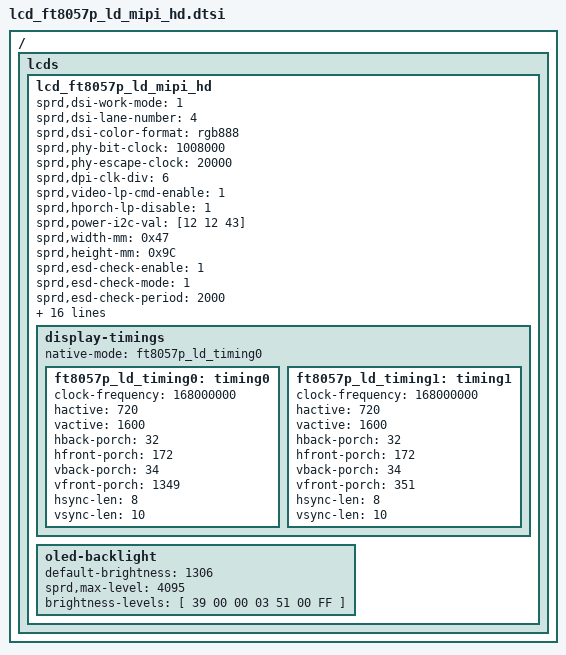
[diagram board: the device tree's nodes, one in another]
/*
 * R61350 Truly LCD config dtsi file for spreadtrum
 *
 * Copyright (C) 2018, Spreadtrum Communications Inc.
 *
 * SPDX-License-Identifier: (GPL-2.0+ OR MIT)
 */

/ {
	fragment {
		target-path = "/";
		__overlay__ {
			lcds {
				lcd_ft8057p_ld_mipi_hd: lcd_ft8057p_ld_mipi_hd {

					sprd,dsi-work-mode = <1>; /* video burst mode*/
					sprd,dsi-lane-number = <4>;
					sprd,dsi-color-format = "rgb888";

					sprd,phy-bit-clock = <1008000>;	/* kbps */
					sprd,phy-escape-clock = <20000>;/* kHz */
					/*add for mipi-6-way frequency mode */
					sprd,dpi-clk-div = <6>;
					sprd,video-lp-cmd-enable = <1>;
					sprd,hporch-lp-disable = <1>;

                                       sprd,power-i2c-val = [12 12 43];

					sprd,width-mm = <0x47>;
					sprd,height-mm = <0x9C>;
					sprd,esd-check-enable = <1>;
					sprd,esd-check-mode = <1>;
					sprd,esd-check-period = <2000>;
					/* sprd,esd-check-register = <0x0A>; */
					/* sprd,esd-check-value = <0x9C>; */

                                       sprd,ft8057-sequence = <1>;
					sprd,reset-on-sequence = <1 5>, <0 5>, <1 30>;
					sprd,reset-off-sequence = <1 5>;
					sprd,use-high-bit-mode = <1>;
					//sprd,use-dcs-write;
					/*
					 * Use 4 bits number for descripting video lp mode, and it can be combined used.
					 * BIT(0): allow vactive enter lp;
					 * BIT(1): allow vfp enter lp;
					 * BIT(2): allow vbp enter lp;
					 * BIT(3): allow vsa enter lp;
					 * For example:
					 * If we need vfp & vbp enter lp, we can calculate this value as a result of BIT(1) | BIT(2)
					 * And we get the result of 3 and set this value to lcd dt property sprd,video-lp-en-mode.
					 * If we need all stage can enter lp, we can calculate this value as a result of BIT(0) | BIT(1) | BIT(2) | BIT(3).
					 * And we get the result of 15 and set this value to lcd dt property sprd,video-lp-en-mode.
					 */
					sprd,video-lp-en-mode = <2>;
					sprd,initial-command = [
					29 00 00 02 00 00
					29 00 00 04 FF 80 57 01
					29 00 00 02 00 80
					29 00 00 03 FF 80 57
					29 00 00 02 00 00
					29 00 00 05 2A 00 00 02 CF
					29 00 00 02 00 00
					29 00 00 05 2B 00 00 06 3F
					29 00 00 02 00 A3
					29 00 00 05 B3 06 40 00 18
					29 00 00 02 00 93
					29 00 00 02 C5 57
					29 00 00 02 00 97
					29 00 00 02 C5 57
					29 00 00 02 00 9A
					29 00 00 02 C5 CB
					29 00 00 02 00 9C
					29 00 00 02 C5 CB
					29 00 00 02 00 B6
					29 00 00 03 C5 43 43
					29 00 00 02 00 B8
					29 00 00 03 C5 41 41
					29 00 00 02 00 00
					29 00 00 03 D8 33 33
					29 00 00 02 00 82
					29 00 00 02 C5 55
					29 00 00 02 00 83
					29 00 00 02 C5 07
					29 00 00 02 00 96
					29 00 00 02 F5 19
					29 00 00 02 00 86
					29 00 00 02 F5 19
					29 00 00 02 00 94
					29 00 00 02 C5 15
					29 00 00 02 00 9B
					29 00 00 02 C5 51
					29 00 00 02 00 A3
					29 00 00 02 A5 04
					29 00 00 02 00 99
					29 00 00 02 CF 56
					29 00 00 02 00 86
					29 00 00 02 B7 80
					29 00 00 02 00 A5
					29 00 00 02 B0 1D
					29 00 00 02 00 90
					29 00 00 02 FF 00
					29 00 00 02 00 00
					29 00 00 11 E1 0D 1A 1C 2C 36 40 51 60 61 6F 73 89 78 64 64 5A
					29 00 00 02 00 10
					29 00 00 09 E1 51 46 38 2E 26 18 14 0F
					29 00 00 02 00 00
					29 00 00 11 E2 0D 1A 1C 2C 36 40 51 60 61 6F 73 89 78 64 64 5A
					29 00 00 02 00 10
					29 00 00 09 E2 51 46 38 2E 26 18 14 0F
					29 00 00 02 00 80
					29 00 00 07 C0 00 D2 00 3A 00 10
					29 00 00 02 00 90
					29 00 00 07 C0 00 9F 00 3A 00 10
					29 00 00 02 00 A0
					29 00 00 07 C0 00 D2 00 3A 00 10
					29 00 00 02 00 B0
					29 00 00 06 C0 01 11 00 3A 10
					29 00 00 02 00 C1
					29 00 00 09 C0 01 33 01 0A 00 CD 01 90
					29 00 00 02 00 70
					29 00 00 07 C0 00 9F 00 3A 00 10
					29 00 00 02 00 A3
					29 00 00 07 C1 00 33 00 3C 00 02
					29 00 00 02 00 B7
					29 00 00 03 C1 00 33
					29 00 00 02 00 73
					29 00 00 03 CE 09 09
					29 00 00 02 00 80
					29 00 00 11 CE 01 81 09 09 00 78 00 96 00 78 00 96 00 78 00 96
					29 00 00 02 00 90
					29 00 00 10 CE 00 A5 16 8F 00 A5 80 09 09 00 07 D0 16 16 27
					29 00 00 02 00 A0
					29 00 00 04 CE 20 00 00
					29 00 00 02 00 B0
					29 00 00 04 CE 87 00 00
					29 00 00 02 00 D1
					29 00 00 08 CE 00 00 01 00 00 00 00
					29 00 00 02 00 E1
					29 00 00 0C CE 08 03 C3 03 C3 02 B0 00 00 00 00
					29 00 00 02 00 F1
					29 00 00 0A CE 14 14 1E 01 45 01 45 01 2B
					29 00 00 02 00 B0
					29 00 00 05 CF 00 00 6D 71
					29 00 00 02 00 B5
					29 00 00 05 CF 03 03 5B 5F
					29 00 00 02 00 C0
					29 00 00 05 CF 06 06 3B 3F
					29 00 00 02 00 C5
					29 00 00 05 CF 06 07 49 4A
					29 00 00 02 00 60
					29 00 00 09 CF 00 00 6D 71 03 03 5B 5F
					29 00 00 02 00 70
					29 00 00 09 CF 00 00 69 6D 03 03 57 5B
					29 00 00 02 00 AA
					29 00 00 05 CF 80 80 10 0C
					29 00 00 02 00 D1
					29 00 00 0D C1 03 AA 05 22 09 59 05 87 08 23 0F AC
					29 00 00 02 00 E1
					29 00 00 03 C1 05 22
					29 00 00 02 00 E2
					29 00 00 0D CF 06 DE 06 DD 06 DD 06 DD 06 DD 06 DD
					29 00 00 02 00 80
					29 00 00 03 C1 00 00
					29 00 00 02 00 90
					29 00 00 02 C1 01
					29 00 00 02 00 F5
					29 00 00 02 CF 01
					29 00 00 02 00 F6
					29 00 00 02 CF 5A
					29 00 00 02 00 F1
					29 00 00 02 CF 5A
					29 00 00 02 00 F7
					29 00 00 02 CF 11
					29 00 00 02 00 00
					29 00 00 03 1F 5A 5A
					29 00 00 02 00 D1
					29 00 00 08 CE 00 13 01 01 00 F2 01
					29 00 00 02 00 E8
					29 00 00 05 CE 00 F2 00 F2
					29 00 00 02 00 80
					29 00 00 11 CC 26 26 1C 1C 26 26 1D 26 26 26 01 07 09 0B 0D 0F
					29 00 00 02 00 90
					29 00 00 09 CC 11 23 05 03 00 00 00 00
					29 00 00 02 00 80
					29 00 00 11 CD 26 26 1C 1C 26 26 1D 26 26 26 01 06 08 0A 0C 0E
					29 00 00 02 00 90
					29 00 00 09 CD 10 22 04 02 00 00 00 00
					29 00 00 02 00 A0
					29 00 00 11 CC 26 26 26 26 1C 1C 1D 26 26 26 01 0C 0A 08 06 10
					29 00 00 02 00 B0
					29 00 00 09 CC 0E 22 02 04 00 00 00 00
					29 00 00 02 00 A0
					29 00 00 11 CD 26 26 26 26 1C 1C 1D 26 26 26 01 0D 0B 09 07 11
					29 00 00 02 00 B0
					29 00 00 09 CD 0F 23 03 05 00 00 00 00
					29 00 00 02 00 80
					29 00 00 11 CB C1 C1 C1 C1 C1 C1 C1 C1 C1 C1 C1 C1 C1 C1 C1 C1
					29 00 00 02 00 ED
					29 00 00 02 CB C1
					29 00 00 02 00 90
					29 00 00 11 CB FF 00 00 00 00 00 00 00 00 00 00 FF 00 00 00 00
					29 00 00 02 00 EE
					29 00 00 02 CB 00
					29 00 00 02 00 90
					29 00 00 02 C3 00
					29 00 00 02 00 A0
					29 00 00 09 CB 00 00 00 00 C0 00 03 00
					29 00 00 02 00 B0
					29 00 00 05 CB 55 55 55 55
					29 00 00 02 00 C0
					29 00 00 05 CB 55 55 55 55
					29 00 00 02 00 D2
					29 00 00 0C CB 01 00 01 01 00 01 01 00 01 01 00
					29 00 00 02 00 E0
					29 00 00 0E CB 01 01 00 01 01 00 01 01 00 01 01 00 01
					29 00 00 02 00 FA
					29 00 00 03 CB 01 00
					29 00 00 02 00 EF
					29 00 00 02 CB 00
					29 00 00 02 00 68
					29 00 00 05 C2 8C 03 00 00
					29 00 00 02 00 6C
					29 00 00 05 C2 8B 03 00 00
					29 00 00 02 00 70
					29 00 00 05 C2 8A 03 00 00
					29 00 00 02 00 74
					29 00 00 05 C2 89 03 00 00
					29 00 00 02 00 EA
					29 00 00 09 C2 12 00 0C 14 00 00 00 00
					29 00 00 02 00 8C
					29 00 00 06 C2 8A 05 15 7A AB
					29 00 00 02 00 91
					29 00 00 06 C2 89 06 15 7A AB
					29 00 00 02 00 96
					29 00 00 06 C2 88 07 15 7A AB
					29 00 00 02 00 9B
					29 00 00 06 C2 87 08 15 7A AB
					29 00 00 02 00 A0
					29 00 00 06 C2 86 09 15 7A AB
					29 00 00 02 00 A5
					29 00 00 06 C2 85 0A 15 7A AB
					29 00 00 02 00 AA
					29 00 00 06 C2 84 0B 15 7A AB
					29 00 00 02 00 AF
					29 00 00 06 C2 83 0C 15 7A AB
					29 00 00 02 00 B4
					29 00 00 06 C2 82 0D 15 7A AB
					29 00 00 02 00 B9
					29 00 00 06 C2 81 0E 15 7A AB
					29 00 00 02 00 BE
					29 00 00 06 C2 80 0F 15 7A AB
					29 00 00 02 00 C3
					29 00 00 06 C2 01 10 15 7A AB
					29 00 00 02 00 DC
					29 00 00 09 C2 BB BB BB BB BB BB 00 00
					29 00 00 02 00 E8
					29 00 00 05 C3 00 00 00 00
					29 00 00 02 00 EC
					29 00 00 05 C3 00 00 00 00
					29 00 00 02 00 F9
					29 00 00 02 CB 20
					29 00 00 02 00 FE
					29 00 00 02 CB 08
					29 00 00 02 00 F8
					29 00 00 04 CD 88 33 87
					29 00 00 02 00 FC
					29 00 00 03 CB 08 40
					29 00 00 02 00 FB
					29 00 00 05 C3 8D 13 8D 13
					29 00 00 02 00 98
					29 00 00 02 C4 08
					29 00 00 02 00 90
					29 00 00 06 E9 10 FF FF FF 00
					29 00 00 02 00 85
					29 00 00 02 C4 80
					29 00 00 02 00 81
					29 00 00 02 A4 73
					29 00 00 02 00 86
					29 00 00 02 A4 B6
					29 00 00 02 00 95
					29 00 00 02 C4 80
					29 00 00 02 00 93
					29 00 00 02 C4 8F
					29 00 00 02 00 80
					29 00 00 02 B3 17
					29 00 00 02 00 A5
					29 00 00 02 B0 1D
					29 00 00 02 00 CA
					29 00 00 03 C0 90 11
					29 00 00 02 00 B7
					29 00 00 02 F5 1D
					29 00 00 02 00 90
					29 00 00 02 C3 00
					29 00 00 02 00 B1
					29 00 00 02 F5 11
					29 00 00 02 00 B0
					29 00 00 02 C5 00
					29 00 00 02 00 B3
					29 00 00 02 C5 00
					29 00 00 02 00 B2
					29 00 00 02 C5 0D
					29 00 00 02 00 B5
					29 00 00 02 C5 02
					29 00 00 02 00 C2
					29 00 00 02 F5 42
					29 00 00 02 00 80
					29 00 00 02 CE 00
					29 00 00 02 00 D0
					29 00 00 02 CE 01
					29 00 00 02 00 E0
					29 00 00 02 CE 00
					29 00 00 02 00 A1
					29 00 00 02 C1 CC
					29 00 00 02 00 A6
					29 00 00 02 C1 10
					29 00 00 02 00 71
					29 00 00 06 C0 9F 01 17 00 22
					29 00 00 02 00 AD
					29 00 00 03 C1 A0 A0
					29 00 00 02 00 84
					29 00 00 02 C5 66
					29 00 00 02 00 80
					29 00 00 02 A4 16
					29 00 00 02 00 8A
					29 00 00 02 C5 06
					29 00 00 02 00 94
					29 00 00 02 C5 13
					29 00 00 02 00 9B
					29 00 00 02 C5 31
					29 00 00 02 00 A8
					29 00 00 02 C1 01
					29 00 00 02 00 BC
					29 00 00 02 C0 01
					29 00 00 02 1C 03
					29 00 00 02 00 B0
					29 00 00 07 CA 00 00 0C 00 00 03
					29 00 00 02 00 C5
					29 00 00 05 CF 06 06 40 44
					29 00 00 02 00 A0
                                        29 00 00 04 CA 06 06 06
					29 00 00 02 00 96
					29 00 00 02 F5 00
					29 00 00 02 00 00
					29 00 00 04 FF 00 00 00
					29 00 00 02 00 80
					29 00 00 03 FF 00 00
					29 00 00 03 51 00 00
					29 00 00 02 53 2C
					29 00 00 02 55 00
					29 00 00 02 35 00
					29 00 00 02 00 00
					29 00 00 04 FF 80 57 01
                                        29 00 00 02 00 80
                                        29 00 00 03 FF 80 57  // CMD2 enable
                                        29 00 00 02 00 80
                                        29 00 00 0D CA D2 D2 C1 B4 AA A1 9A 93 8E 89 84 80
                                        29 00 00 02 00 90
                                        29 00 00 0A CA FC 73 CC E8 13 CC FA FF 66
					05 5A 00 01 11
					05 01 00 01 29
						];

					sprd,sleep-in-command = [
						05 14 00 01 28
						05 78 00 01 10
						29 00 00 02 00 00
						29 03 00 05 F7 5A A5 95 27
						];

					sprd,sleep-out-command = [
						05 5A 00 01 11
						05 01 00 01 29
						];

					sprd,cabc-off-command = [
						23 00 00 02 55 00
						];
					sprd,cabc-ui-command = [
						23 00 00 02 55 01
						];
					sprd,cabc-still-command = [
						23 00 00 02 55 02
						];
					sprd,cabc-moving-command = [
						23 00 00 02 55 03
						];


					display-timings {
						native-mode = <&ft8057p_ld_timing0>;

						ft8057p_ld_timing0: timing0 {
							clock-frequency = <168000000>;
							hactive = <720>;
							vactive = <1600>;
							hback-porch = <32>;
							hfront-porch = <172>;
							vback-porch = <34>;
							vfront-porch = <1349>;
							hsync-len = <8>;
							vsync-len = <10>;
						};

						ft8057p_ld_timing1: timing1 {
							clock-frequency = <168000000>;
							hactive = <720>;
							vactive = <1600>;
							hback-porch = <32>;
							hfront-porch = <172>;
							vback-porch = <34>;
							vfront-porch = <351>;
							hsync-len = <8>;
							vsync-len = <10>;
						};
					};
					oled-backlight {
						default-brightness = <1306>;
						sprd,max-level = <4095>;
						brightness-levels = [
            		    	39 00 00 03 51 00 FF
						];
					};
				};
			};
		};
	};
};
